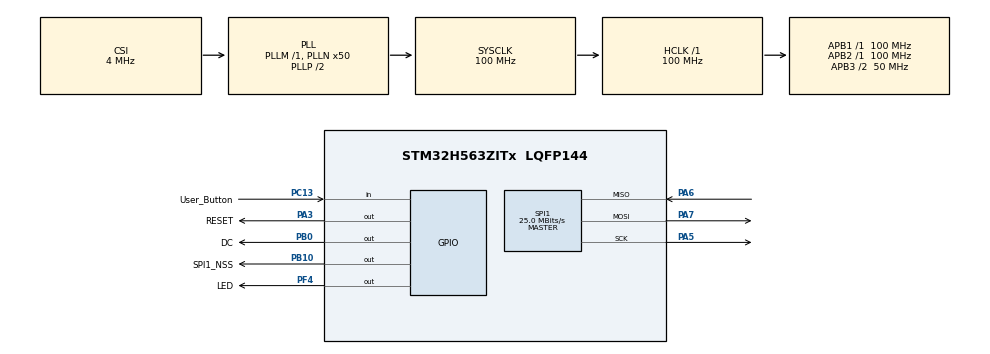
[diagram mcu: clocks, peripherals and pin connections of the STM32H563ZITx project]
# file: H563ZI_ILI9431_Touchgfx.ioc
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BOOTPATH.BootPathName=LEGACY
BOOTPATH.UserSelectedBootPath=LEGACY
CORTEX_M33_NS.userName=CORTEX_M33
GPDMA2.CIRCULARMODE_GPDMACH0=DISABLE
GPDMA2.DESTINC_GPDMACH0=DMA_DINC_FIXED
GPDMA2.DIRECTION_GPDMACH0=DMA_MEMORY_TO_PERIPH
GPDMA2.IPHANDLE_GPDMACH0-SIMPLEREQUEST_GPDMACH0=__NULL
GPDMA2.REQUEST_GPDMACH0=GPDMA2_REQUEST_SPI1_TX
GPDMA2.SRCINC_GPDMACH0=DMA_SINC_INCREMENTED
GPDMA2.TRANSFERALLOCATEDPORTDEST_GPDMACH0=DMA_DEST_ALLOCATED_PORT1
ICACHE.Region=_NULL
Mcu.Family=STM32H5
Mcu.Name=STM32H563ZITx
Mcu.Package=LQFP144
NVIC.GPDMA2_Channel0_IRQn=true\:0\:0\:false\:false\:true\:false\:true\:true
NVIC.PriorityGroup=NVIC_PRIORITYGROUP_4
NVIC.SPI1_IRQn=true\:0\:0\:false\:false\:true\:true\:true\:true
NVIC.TIM2_IRQn=true\:0\:0\:false\:false\:true\:true\:true\:true
NVIC.TIM7_IRQn=true\:15\:0\:false\:false\:true\:false\:true\:true
NVIC.TimeBase=TIM7_IRQn
NVIC.TimeBaseIP=TIM7
PA3.GPIO_Label=RESET
PA3.Signal=GPIO_Output
PA5.Mode=Full_Duplex_Master
PA5.Signal=SPI1_SCK
PA6.Mode=Full_Duplex_Master
PA6.Signal=SPI1_MISO
PA7.Mode=Full_Duplex_Master
PA7.Signal=SPI1_MOSI
PB0.GPIO_Label=DC
PB0.Signal=GPIO_Output
PB10.GPIO_Label=SPI1_NSS
PB10.Signal=GPIO_Output
PC13.GPIO_Label=User_Button
PC13.Signal=GPIO_Input
PF4.GPIO_Label=LED
PF4.Signal=GPIO_Output
ProjectManager.HeapSize=0x200
ProjectManager.StackSize=0x400
ProjectManager.TargetToolchain=STM32CubeIDE
RCC.ADCFreq_Value=100000000
RCC.AHBFreq_Value=100000000
RCC.APB1Freq_Value=100000000
RCC.APB1TimFreq_Value=100000000
RCC.APB2Freq_Value=100000000
RCC.APB2TimFreq_Value=100000000
RCC.APB3CLKDivider=RCC_HCLK_DIV2
RCC.APB3Freq_Value=50000000
RCC.CSI_VALUE=4000000
RCC.CortexFreq_Value=100000000
RCC.EPOD_VALUE=4000000
RCC.HCLKFreq_Value=100000000
RCC.HSE_VALUE=8000000
RCC.HSI48_VALUE=48000000
RCC.HSIDiv=RCC_HSI_DIV1
RCC.HSI_VALUE=64000000
RCC.LSE_VALUE=32768
RCC.LSIRC_VALUE=32000
RCC.PLL1Q=4
RCC.PLLFRACN=0
RCC.PLLN=50
RCC.SYSCLKFreq_VALUE=100000000
RCC.SYSCLKSource=RCC_SYSCLKSOURCE_PLLCLK
RCC.USBFreq_Value=48000000
RCC.VCOOutputFreq_Value=200000000
SPI1.CalculateBaudRate=25.0 MBits/s
SPI1.DataSize=SPI_DATASIZE_8BIT
SPI1.Direction=SPI_DIRECTION_2LINES
SPI1.Mode=SPI_MODE_MASTER
SPI1.VirtualType=VM_MASTER
STMicroelectronics.X-CUBE-TOUCHGFX.4.25.0.ApplicationCcGraphicsJjApplication=TouchGFXOoGenerator
STMicroelectronics.X-CUBE-TOUCHGFX.4.25.0.tgfx_buffering_strategy=Partial
STMicroelectronics.X-CUBE-TOUCHGFX.4.25.0.tgfx_custom_height=240
STMicroelectronics.X-CUBE-TOUCHGFX.4.25.0.tgfx_custom_width=320
STMicroelectronics.X-CUBE-TOUCHGFX.4.25.0_IsPackSelfContextualization=true
TIM2.PeriodNoDither=50000-1
TIM2.Prescaler=100-1
VP_BOOTPATH_VS_BOOTPATH.Mode=BP_Activate
VP_CORTEX_M33_NS_VS_Hclk.Mode=Hclk_Mode
VP_CRC_VS_CRC.Mode=CRC_Activate
VP_GPDMA2_VS_GPDMACH0.Mode=SIMPLEREQUEST_GPDMACH0
VP_ICACHE_VS_ENABLE_ICACHE_MEMORY.Mode=Memoryregions
VP_ICACHE_VS_ICACHE.Mode=DefaultMode
VP_MEMORYMAP_VS_MEMORYMAP.Mode=CurAppReg
VP_PWR_VS_LPOM.Mode=PowerOptimisation
VP_PWR_VS_SECSignals.Mode=Security/Privilege
VP_STMicroelectronics.X-CUBE-TOUCHGFX_VS_GraphicsJjApplication_4.25.0.Mode=GraphicsJjApplication
VP_SYS_VS_tim7.Mode=TIM7
VP_TIM2_VS_ClockSourceINT.Mode=Internal
board=NUCLEO-H563ZI

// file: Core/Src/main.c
/* USER CODE BEGIN Header */
/**
  ******************************************************************************
  * @file           : main.c
  * @brief          : Main program body
  ******************************************************************************
  * @attention
  *
  * Copyright (c) 2025 STMicroelectronics.
  * All rights reserved.
  *
  * This software is licensed under terms that can be found in the LICENSE file
  * in the root directory of this software component.
  * If no LICENSE file comes with this software, it is provided AS-IS.
  *
  ******************************************************************************
  */
/* USER CODE END Header */
#include "main.h"
#include "app_touchgfx.h"

/* USER CODE BEGIN Includes */
#include "ili9341.h"
/* USER CODE END Includes */

CRC_HandleTypeDef hcrc;

SPI_HandleTypeDef hspi1;
DMA_HandleTypeDef handle_GPDMA2_Channel0;

TIM_HandleTypeDef htim2;

void SystemClock_Config(void);
static void MX_GPIO_Init(void);
static void MX_GPDMA2_Init(void);
static void MX_CRC_Init(void);
static void MX_TIM2_Init(void);
static void MX_ICACHE_Init(void);
static void MX_SPI1_Init(void);

int main(void)
{

  /* MCU Configuration--------------------------------------------------------*/

  /* Reset of all peripherals, Initializes the Flash interface and the Systick. */
  HAL_Init();

  /* Configure the system clock */
  SystemClock_Config();

  /* Initialize all configured peripherals */
  MX_GPIO_Init();
  MX_GPDMA2_Init();
  MX_CRC_Init();
  MX_TIM2_Init();
  MX_ICACHE_Init();
  MX_SPI1_Init();
  MX_TouchGFX_Init();
  /* USER CODE BEGIN 2 */
  HAL_TIM_Base_Start_IT(&htim2);
  ILI9341_Init();
  /* USER CODE END 2 */

  /* Infinite loop */
  while (1)
  {

  MX_TouchGFX_Process();
  }
}

void SystemClock_Config(void)
{
  RCC_OscInitTypeDef RCC_OscInitStruct = {0};
  RCC_ClkInitTypeDef RCC_ClkInitStruct = {0};

  /** Configure the main internal regulator output voltage
  */
  __HAL_PWR_VOLTAGESCALING_CONFIG(PWR_REGULATOR_VOLTAGE_SCALE3);

  while(!__HAL_PWR_GET_FLAG(PWR_FLAG_VOSRDY)) {}

  /** Initializes the RCC Oscillators according to the specified parameters
  * in the RCC_OscInitTypeDef structure.
  */
  RCC_OscInitStruct.OscillatorType = RCC_OSCILLATORTYPE_CSI;
  RCC_OscInitStruct.CSIState = RCC_CSI_ON;
  RCC_OscInitStruct.CSICalibrationValue = RCC_CSICALIBRATION_DEFAULT;
  RCC_OscInitStruct.PLL.PLLState = RCC_PLL_ON;
  RCC_OscInitStruct.PLL.PLLSource = RCC_PLL1_SOURCE_CSI;
  RCC_OscInitStruct.PLL.PLLM = 1;
  RCC_OscInitStruct.PLL.PLLN = 50;
  RCC_OscInitStruct.PLL.PLLP = 2;
  RCC_OscInitStruct.PLL.PLLQ = 4;
  RCC_OscInitStruct.PLL.PLLR = 2;
  RCC_OscInitStruct.PLL.PLLRGE = RCC_PLL1_VCIRANGE_2;
  RCC_OscInitStruct.PLL.PLLVCOSEL = RCC_PLL1_VCORANGE_WIDE;
  RCC_OscInitStruct.PLL.PLLFRACN = 0;
  if (HAL_RCC_OscConfig(&RCC_OscInitStruct) != HAL_OK)
  {
    Error_Handler();
  }

  /** Initializes the CPU, AHB and APB buses clocks
  */
  RCC_ClkInitStruct.ClockType = RCC_CLOCKTYPE_HCLK|RCC_CLOCKTYPE_SYSCLK
                              |RCC_CLOCKTYPE_PCLK1|RCC_CLOCKTYPE_PCLK2
                              |RCC_CLOCKTYPE_PCLK3;
  RCC_ClkInitStruct.SYSCLKSource = RCC_SYSCLKSOURCE_PLLCLK;
  RCC_ClkInitStruct.AHBCLKDivider = RCC_SYSCLK_DIV1;
  RCC_ClkInitStruct.APB1CLKDivider = RCC_HCLK_DIV1;
  RCC_ClkInitStruct.APB2CLKDivider = RCC_HCLK_DIV1;
  RCC_ClkInitStruct.APB3CLKDivider = RCC_HCLK_DIV2;

  if (HAL_RCC_ClockConfig(&RCC_ClkInitStruct, FLASH_LATENCY_4) != HAL_OK)
  {
    Error_Handler();
  }

  /** Configure the programming delay
  */
  __HAL_FLASH_SET_PROGRAM_DELAY(FLASH_PROGRAMMING_DELAY_2);
}

static void MX_CRC_Init(void)
{

  hcrc.Instance = CRC;
  hcrc.Init.DefaultPolynomialUse = DEFAULT_POLYNOMIAL_ENABLE;
  hcrc.Init.DefaultInitValueUse = DEFAULT_INIT_VALUE_ENABLE;
  hcrc.Init.InputDataInversionMode = CRC_INPUTDATA_INVERSION_NONE;
  hcrc.Init.OutputDataInversionMode = CRC_OUTPUTDATA_INVERSION_DISABLE;
  hcrc.InputDataFormat = CRC_INPUTDATA_FORMAT_BYTES;
  if (HAL_CRC_Init(&hcrc) != HAL_OK)
  {
    Error_Handler();
  }

}

static void MX_GPDMA2_Init(void)
{

  /* Peripheral clock enable */
  __HAL_RCC_GPDMA2_CLK_ENABLE();

  /* GPDMA2 interrupt Init */
    HAL_NVIC_SetPriority(GPDMA2_Channel0_IRQn, 0, 0);
    HAL_NVIC_EnableIRQ(GPDMA2_Channel0_IRQn);

}

static void MX_ICACHE_Init(void)
{

  /** Enable instruction cache (default 2-ways set associative cache)
  */
  if (HAL_ICACHE_Enable() != HAL_OK)
  {
    Error_Handler();
  }

}

static void MX_SPI1_Init(void)
{

  /* SPI1 parameter configuration*/
  hspi1.Instance = SPI1;
  hspi1.Init.Mode = SPI_MODE_MASTER;
  hspi1.Init.Direction = SPI_DIRECTION_2LINES;
  hspi1.Init.DataSize = SPI_DATASIZE_8BIT;
  hspi1.Init.CLKPolarity = SPI_POLARITY_LOW;
  hspi1.Init.CLKPhase = SPI_PHASE_1EDGE;
  hspi1.Init.NSS = SPI_NSS_SOFT;
  hspi1.Init.BaudRatePrescaler = SPI_BAUDRATEPRESCALER_2;
  hspi1.Init.FirstBit = SPI_FIRSTBIT_MSB;
  hspi1.Init.TIMode = SPI_TIMODE_DISABLE;
  hspi1.Init.CRCCalculation = SPI_CRCCALCULATION_DISABLE;
  hspi1.Init.CRCPolynomial = 0x7;
  hspi1.Init.NSSPMode = SPI_NSS_PULSE_ENABLE;
  hspi1.Init.NSSPolarity = SPI_NSS_POLARITY_LOW;
  hspi1.Init.FifoThreshold = SPI_FIFO_THRESHOLD_01DATA;
  hspi1.Init.MasterSSIdleness = SPI_MASTER_SS_IDLENESS_00CYCLE;
  hspi1.Init.MasterInterDataIdleness = SPI_MASTER_INTERDATA_IDLENESS_00CYCLE;
  hspi1.Init.MasterReceiverAutoSusp = SPI_MASTER_RX_AUTOSUSP_DISABLE;
  hspi1.Init.MasterKeepIOState = SPI_MASTER_KEEP_IO_STATE_DISABLE;
  hspi1.Init.IOSwap = SPI_IO_SWAP_DISABLE;
  hspi1.Init.ReadyMasterManagement = SPI_RDY_MASTER_MANAGEMENT_INTERNALLY;
  hspi1.Init.ReadyPolarity = SPI_RDY_POLARITY_HIGH;
  if (HAL_SPI_Init(&hspi1) != HAL_OK)
  {
    Error_Handler();
  }

}

static void MX_TIM2_Init(void)
{

  TIM_ClockConfigTypeDef sClockSourceConfig = {0};
  TIM_MasterConfigTypeDef sMasterConfig = {0};

  htim2.Instance = TIM2;
  htim2.Init.Prescaler = 100-1;
  htim2.Init.CounterMode = TIM_COUNTERMODE_UP;
  htim2.Init.Period = 49999;
  htim2.Init.ClockDivision = TIM_CLOCKDIVISION_DIV1;
  htim2.Init.AutoReloadPreload = TIM_AUTORELOAD_PRELOAD_DISABLE;
  if (HAL_TIM_Base_Init(&htim2) != HAL_OK)
  {
    Error_Handler();
  }
  sClockSourceConfig.ClockSource = TIM_CLOCKSOURCE_INTERNAL;
  if (HAL_TIM_ConfigClockSource(&htim2, &sClockSourceConfig) != HAL_OK)
  {
    Error_Handler();
  }
  sMasterConfig.MasterOutputTrigger = TIM_TRGO_RESET;
  sMasterConfig.MasterSlaveMode = TIM_MASTERSLAVEMODE_DISABLE;
  if (HAL_TIMEx_MasterConfigSynchronization(&htim2, &sMasterConfig) != HAL_OK)
  {
    Error_Handler();
  }

}

static void MX_GPIO_Init(void)
{
  GPIO_InitTypeDef GPIO_InitStruct = {0};

  /* GPIO Ports Clock Enable */
  __HAL_RCC_GPIOC_CLK_ENABLE();
  __HAL_RCC_GPIOF_CLK_ENABLE();
  __HAL_RCC_GPIOA_CLK_ENABLE();
  __HAL_RCC_GPIOB_CLK_ENABLE();

  /*Configure GPIO pin Output Level */
  HAL_GPIO_WritePin(LED_GPIO_Port, LED_Pin, GPIO_PIN_RESET);

  /*Configure GPIO pin Output Level */
  HAL_GPIO_WritePin(RESET_GPIO_Port, RESET_Pin, GPIO_PIN_RESET);

  /*Configure GPIO pin Output Level */
  HAL_GPIO_WritePin(GPIOB, DC_Pin|SPI1_NSS_Pin, GPIO_PIN_RESET);

  /*Configure GPIO pin : User_Button_Pin */
  GPIO_InitStruct.Pin = User_Button_Pin;
  GPIO_InitStruct.Mode = GPIO_MODE_INPUT;
  GPIO_InitStruct.Pull = GPIO_NOPULL;
  HAL_GPIO_Init(User_Button_GPIO_Port, &GPIO_InitStruct);

  /*Configure GPIO pin : LED_Pin */
  GPIO_InitStruct.Pin = LED_Pin;
  GPIO_InitStruct.Mode = GPIO_MODE_OUTPUT_PP;
  GPIO_InitStruct.Pull = GPIO_NOPULL;
  GPIO_InitStruct.Speed = GPIO_SPEED_FREQ_LOW;
  HAL_GPIO_Init(LED_GPIO_Port, &GPIO_InitStruct);

  /*Configure GPIO pin : RESET_Pin */
  GPIO_InitStruct.Pin = RESET_Pin;
  GPIO_InitStruct.Mode = GPIO_MODE_OUTPUT_PP;
  GPIO_InitStruct.Pull = GPIO_NOPULL;
  GPIO_InitStruct.Speed = GPIO_SPEED_FREQ_LOW;
  HAL_GPIO_Init(RESET_GPIO_Port, &GPIO_InitStruct);

  /*Configure GPIO pins : DC_Pin SPI1_NSS_Pin */
  GPIO_InitStruct.Pin = DC_Pin|SPI1_NSS_Pin;
  GPIO_InitStruct.Mode = GPIO_MODE_OUTPUT_PP;
  GPIO_InitStruct.Pull = GPIO_NOPULL;
  GPIO_InitStruct.Speed = GPIO_SPEED_FREQ_LOW;
  HAL_GPIO_Init(GPIOB, &GPIO_InitStruct);

}

void HAL_TIM_PeriodElapsedCallback(TIM_HandleTypeDef *htim)
{
  /* USER CODE BEGIN Callback 0 */
	extern void touchgfxSignalVSync(void);
		if (htim->Instance == TIM2)
		{
			touchgfxSignalVSync();
		}
  /* USER CODE END Callback 0 */
  if (htim->Instance == TIM7)
  {
    HAL_IncTick();
  }
}

void Error_Handler(void)
{
  __disable_irq();
  while (1)
  {
  }
}
